AUTOSAR XML (schema 00048)
package /ComponentTypes
  swc implementation AMP_Implementation: behavior=AMP_InternalBehavior
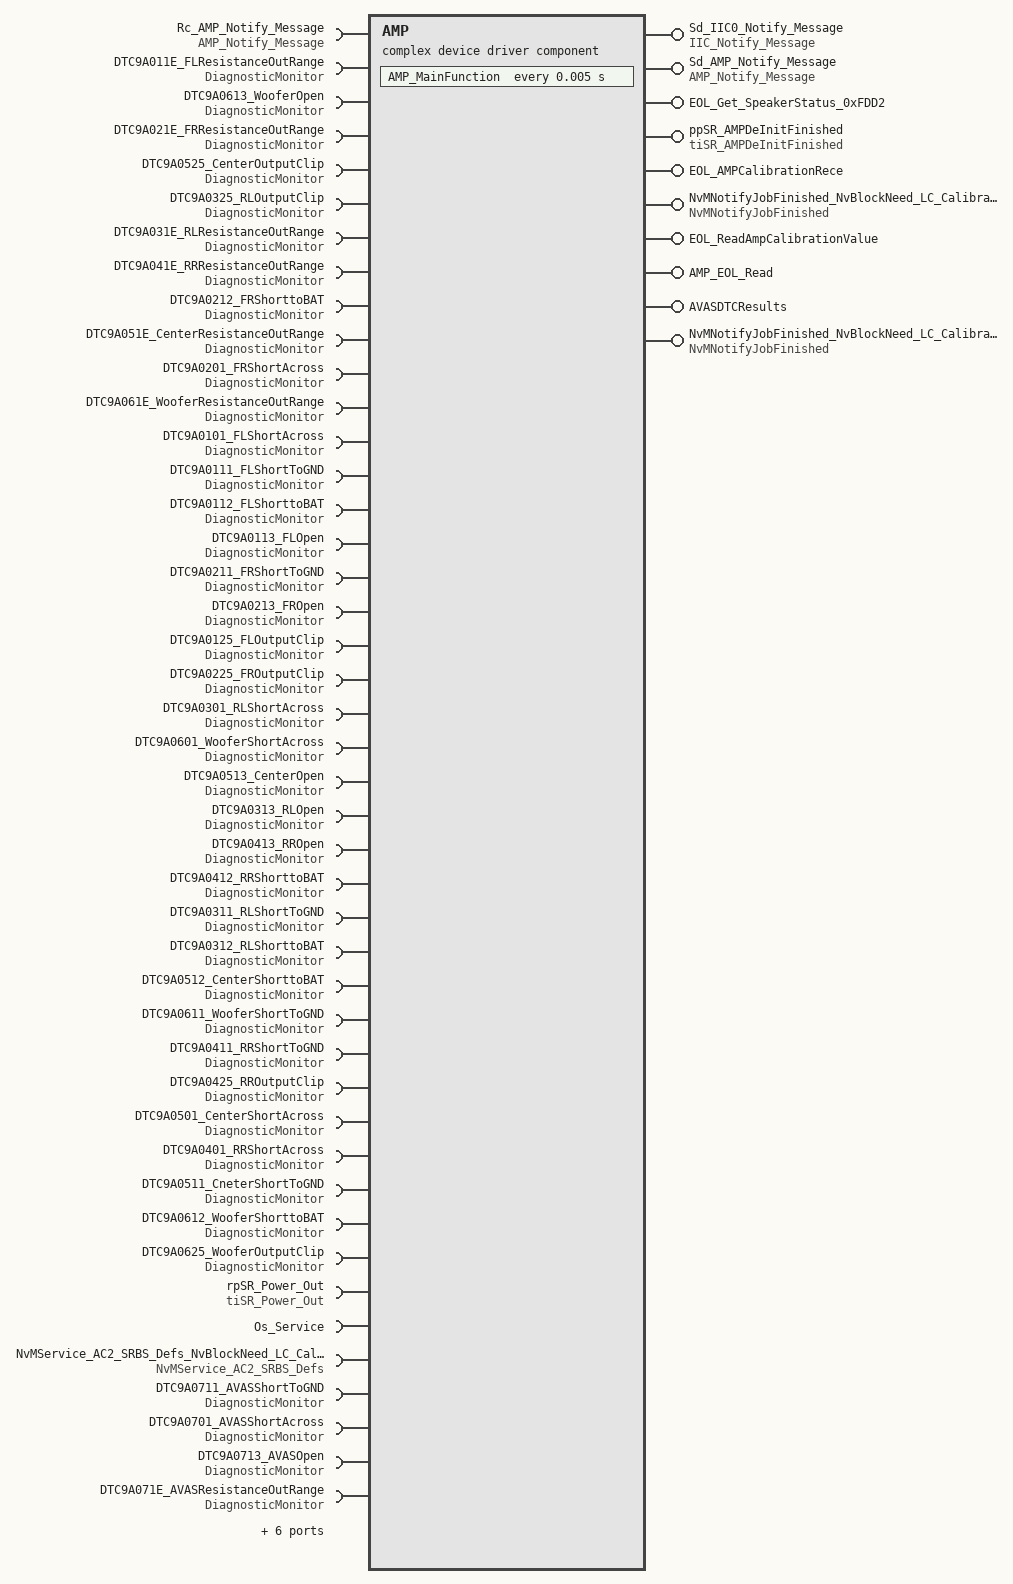
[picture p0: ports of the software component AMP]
  complex device driver sw component type AMP
    provide port Sd_IIC0_Notify_Message: queued-sender-com-spec=Message, provided-interface=IIC_Notify_Message
    provide port Sd_AMP_Notify_Message: nonqueued-sender-com-spec{data-element=Element, init-value=0}, provided-interface=AMP_Notify_Message
    require port Rc_AMP_Notify_Message: nonqueued-receiver-com-spec{data-element=Element, filter=data-filter-type=ALWAYS, init-value=0}, required-interface=AMP_Notify_Message
    provide port EOL_Get_SpeakerStatus_0xFDD2: server-com-spec{operation=EOL_Get_SpeakerStatus_0xFDD2, queue-length=1}, provided-interface=EOL_Get_SpeakerStatus_0xFDD2
    36 x require port, all with required-interface=DiagnosticMonitor:
      DTC9A011E_FLResistanceOutRange
        required-com-specs:
          GetEventExtendedDataRecordEx
          GetEventFreezeFrameDataEx
          GetFaultDetectionCounter
          GetDTCOfEvent
          GetEventTested
          GetEventFailed
          GetEventStatus
          GetEventUdsStatus
          ResetEventDebounceStatus
          ResetEventStatus
          SetEventStatus
      DTC9A0613_WooferOpen
        required-com-specs:
          GetEventExtendedDataRecordEx
          GetEventFreezeFrameDataEx
          GetFaultDetectionCounter
          GetDTCOfEvent
          GetEventTested
          GetEventFailed
          GetEventStatus
          GetEventUdsStatus
          ResetEventDebounceStatus
          ResetEventStatus
          SetEventStatus
      DTC9A021E_FRResistanceOutRange
        required-com-specs:
          GetEventExtendedDataRecordEx
          GetEventFreezeFrameDataEx
          GetFaultDetectionCounter
          GetDTCOfEvent
          GetEventTested
          GetEventFailed
          GetEventStatus
          GetEventUdsStatus
          ResetEventDebounceStatus
          ResetEventStatus
          SetEventStatus
      DTC9A0525_CenterOutputClip
        required-com-specs:
          GetEventExtendedDataRecordEx
          GetEventFreezeFrameDataEx
          GetFaultDetectionCounter
          GetDTCOfEvent
          GetEventTested
          GetEventFailed
          GetEventStatus
          GetEventUdsStatus
          ResetEventDebounceStatus
          ResetEventStatus
          SetEventStatus
      DTC9A0325_RLOutputClip
        required-com-specs:
          GetEventExtendedDataRecordEx
          GetEventFreezeFrameDataEx
          GetFaultDetectionCounter
          GetDTCOfEvent
          GetEventTested
          GetEventFailed
          GetEventStatus
          GetEventUdsStatus
          ResetEventDebounceStatus
          ResetEventStatus
          SetEventStatus
      DTC9A031E_RLResistanceOutRange
        required-com-specs:
          GetEventExtendedDataRecordEx
          GetEventFreezeFrameDataEx
          GetFaultDetectionCounter
          GetDTCOfEvent
          GetEventTested
          GetEventFailed
          GetEventStatus
          GetEventUdsStatus
          ResetEventDebounceStatus
          ResetEventStatus
          SetEventStatus
      DTC9A041E_RRResistanceOutRange
        required-com-specs:
          GetEventExtendedDataRecordEx
          GetEventFreezeFrameDataEx
          GetFaultDetectionCounter
          GetDTCOfEvent
          GetEventTested
          GetEventFailed
          GetEventStatus
          GetEventUdsStatus
          ResetEventDebounceStatus
          ResetEventStatus
          SetEventStatus
      DTC9A0212_FRShorttoBAT
        required-com-specs:
          GetEventExtendedDataRecordEx
          GetEventFreezeFrameDataEx
          GetFaultDetectionCounter
          GetDTCOfEvent
          GetEventTested
          GetEventFailed
          GetEventStatus
          GetEventUdsStatus
          ResetEventDebounceStatus
          ResetEventStatus
          SetEventStatus
      DTC9A051E_CenterResistanceOutRange
        required-com-specs:
          GetEventExtendedDataRecordEx
          GetEventFreezeFrameDataEx
          GetFaultDetectionCounter
          GetDTCOfEvent
          GetEventTested
          GetEventFailed
          GetEventStatus
          GetEventUdsStatus
          ResetEventDebounceStatus
          ResetEventStatus
          SetEventStatus
      DTC9A0201_FRShortAcross
        required-com-specs:
          GetEventExtendedDataRecordEx
          GetEventFreezeFrameDataEx
          GetFaultDetectionCounter
          GetDTCOfEvent
          GetEventTested
          GetEventFailed
          GetEventStatus
          GetEventUdsStatus
          ResetEventDebounceStatus
          ResetEventStatus
          SetEventStatus
      DTC9A061E_WooferResistanceOutRange
        required-com-specs:
          GetEventExtendedDataRecordEx
          GetEventFreezeFrameDataEx
          GetFaultDetectionCounter
          GetDTCOfEvent
          GetEventTested
          GetEventFailed
          GetEventStatus
          GetEventUdsStatus
          ResetEventDebounceStatus
          ResetEventStatus
          SetEventStatus
      DTC9A0101_FLShortAcross
        required-com-specs:
          GetEventExtendedDataRecordEx
          GetEventFreezeFrameDataEx
          GetFaultDetectionCounter
          GetDTCOfEvent
          GetEventTested
          GetEventFailed
          GetEventStatus
          GetEventUdsStatus
          ResetEventDebounceStatus
          ResetEventStatus
          SetEventStatus
      DTC9A0111_FLShortToGND
        required-com-specs:
          GetEventExtendedDataRecordEx
          GetEventFreezeFrameDataEx
          GetFaultDetectionCounter
          GetDTCOfEvent
          GetEventTested
          GetEventFailed
          GetEventStatus
          GetEventUdsStatus
          ResetEventDebounceStatus
          ResetEventStatus
          SetEventStatus
      DTC9A0112_FLShorttoBAT
        required-com-specs:
          GetEventExtendedDataRecordEx
          GetEventFreezeFrameDataEx
          GetFaultDetectionCounter
          GetDTCOfEvent
          GetEventTested
          GetEventFailed
          GetEventStatus
          GetEventUdsStatus
          ResetEventDebounceStatus
          ResetEventStatus
          SetEventStatus
      DTC9A0113_FLOpen
        required-com-specs:
          GetEventExtendedDataRecordEx
          GetEventFreezeFrameDataEx
          GetFaultDetectionCounter
          GetDTCOfEvent
          GetEventTested
          GetEventFailed
          GetEventStatus
          GetEventUdsStatus
          ResetEventDebounceStatus
          ResetEventStatus
          SetEventStatus
      DTC9A0211_FRShortToGND
        required-com-specs:
          GetEventExtendedDataRecordEx
          GetEventFreezeFrameDataEx
          GetFaultDetectionCounter
          GetDTCOfEvent
          GetEventTested
          GetEventFailed
          GetEventStatus
          GetEventUdsStatus
          ResetEventDebounceStatus
          ResetEventStatus
          SetEventStatus
      DTC9A0213_FROpen
        required-com-specs:
          GetEventExtendedDataRecordEx
          GetEventFreezeFrameDataEx
          GetFaultDetectionCounter
          GetDTCOfEvent
          GetEventTested
          GetEventFailed
          GetEventStatus
          GetEventUdsStatus
          ResetEventDebounceStatus
          ResetEventStatus
          SetEventStatus
      DTC9A0125_FLOutputClip
        required-com-specs:
          GetEventExtendedDataRecordEx
          GetEventFreezeFrameDataEx
          GetFaultDetectionCounter
          GetDTCOfEvent
          GetEventTested
          GetEventFailed
          GetEventStatus
          GetEventUdsStatus
          ResetEventDebounceStatus
          ResetEventStatus
          SetEventStatus
      DTC9A0225_FROutputClip
        required-com-specs:
          GetEventExtendedDataRecordEx
          GetEventFreezeFrameDataEx
          GetFaultDetectionCounter
          GetDTCOfEvent
          GetEventTested
          GetEventFailed
          GetEventStatus
          GetEventUdsStatus
          ResetEventDebounceStatus
          ResetEventStatus
          SetEventStatus
      DTC9A0301_RLShortAcross
        required-com-specs:
          GetEventExtendedDataRecordEx
          GetEventFreezeFrameDataEx
          GetFaultDetectionCounter
          GetDTCOfEvent
          GetEventTested
          GetEventFailed
          GetEventStatus
          GetEventUdsStatus
          ResetEventDebounceStatus
          ResetEventStatus
          SetEventStatus
      DTC9A0601_WooferShortAcross
        required-com-specs:
          GetEventExtendedDataRecordEx
          GetEventFreezeFrameDataEx
          GetFaultDetectionCounter
          GetDTCOfEvent
          GetEventTested
          GetEventFailed
          GetEventStatus
          GetEventUdsStatus
          ResetEventDebounceStatus
          ResetEventStatus
          SetEventStatus
      DTC9A0513_CenterOpen
        required-com-specs:
          GetEventExtendedDataRecordEx
          GetEventFreezeFrameDataEx
          GetFaultDetectionCounter
          GetDTCOfEvent
          GetEventTested
          GetEventFailed
          GetEventStatus
          GetEventUdsStatus
          ResetEventDebounceStatus
          ResetEventStatus
          SetEventStatus
      DTC9A0313_RLOpen
        required-com-specs:
          GetEventExtendedDataRecordEx
          GetEventFreezeFrameDataEx
          GetFaultDetectionCounter
          GetDTCOfEvent
          GetEventTested
          GetEventFailed
          GetEventStatus
          GetEventUdsStatus
          ResetEventDebounceStatus
          ResetEventStatus
          SetEventStatus
      DTC9A0413_RROpen
        required-com-specs:
          GetEventExtendedDataRecordEx
          GetEventFreezeFrameDataEx
          GetFaultDetectionCounter
          GetDTCOfEvent
          GetEventTested
          GetEventFailed
          GetEventStatus
          GetEventUdsStatus
          ResetEventDebounceStatus
          ResetEventStatus
          SetEventStatus
      DTC9A0412_RRShorttoBAT
        required-com-specs:
          GetEventExtendedDataRecordEx
          GetEventFreezeFrameDataEx
          GetFaultDetectionCounter
          GetDTCOfEvent
          GetEventTested
          GetEventFailed
          GetEventStatus
          GetEventUdsStatus
          ResetEventDebounceStatus
          ResetEventStatus
          SetEventStatus
      DTC9A0311_RLShortToGND
        required-com-specs:
          GetEventExtendedDataRecordEx
          GetEventFreezeFrameDataEx
          GetFaultDetectionCounter
          GetDTCOfEvent
          GetEventTested
          GetEventFailed
          GetEventStatus
          GetEventUdsStatus
          ResetEventDebounceStatus
          ResetEventStatus
          SetEventStatus
      DTC9A0312_RLShorttoBAT
        required-com-specs:
          GetEventExtendedDataRecordEx
          GetEventFreezeFrameDataEx
          GetFaultDetectionCounter
          GetDTCOfEvent
          GetEventTested
          GetEventFailed
          GetEventStatus
          GetEventUdsStatus
          ResetEventDebounceStatus
          ResetEventStatus
          SetEventStatus
      DTC9A0512_CenterShorttoBAT
        required-com-specs:
          GetEventExtendedDataRecordEx
          GetEventFreezeFrameDataEx
          GetFaultDetectionCounter
          GetDTCOfEvent
          GetEventTested
          GetEventFailed
          GetEventStatus
          GetEventUdsStatus
          ResetEventDebounceStatus
          ResetEventStatus
          SetEventStatus
      DTC9A0611_WooferShortToGND
        required-com-specs:
          GetEventExtendedDataRecordEx
          GetEventFreezeFrameDataEx
          GetFaultDetectionCounter
          GetDTCOfEvent
          GetEventTested
          GetEventFailed
          GetEventStatus
          GetEventUdsStatus
          ResetEventDebounceStatus
          ResetEventStatus
          SetEventStatus
      DTC9A0411_RRShortToGND
        required-com-specs:
          GetEventExtendedDataRecordEx
          GetEventFreezeFrameDataEx
          GetFaultDetectionCounter
          GetDTCOfEvent
          GetEventTested
          GetEventFailed
          GetEventStatus
          GetEventUdsStatus
          ResetEventDebounceStatus
          ResetEventStatus
          SetEventStatus
      DTC9A0425_RROutputClip
        required-com-specs:
          GetEventExtendedDataRecordEx
          GetEventFreezeFrameDataEx
          GetFaultDetectionCounter
          GetDTCOfEvent
          GetEventTested
          GetEventFailed
          GetEventStatus
          GetEventUdsStatus
          ResetEventDebounceStatus
          ResetEventStatus
          SetEventStatus
      DTC9A0501_CenterShortAcross
        required-com-specs:
          GetEventExtendedDataRecordEx
          GetEventFreezeFrameDataEx
          GetFaultDetectionCounter
          GetDTCOfEvent
          GetEventTested
          GetEventFailed
          GetEventStatus
          GetEventUdsStatus
          ResetEventDebounceStatus
          ResetEventStatus
          SetEventStatus
      DTC9A0401_RRShortAcross
        required-com-specs:
          GetEventExtendedDataRecordEx
          GetEventFreezeFrameDataEx
          GetFaultDetectionCounter
          GetDTCOfEvent
          GetEventTested
          GetEventFailed
          GetEventStatus
          GetEventUdsStatus
          ResetEventDebounceStatus
          ResetEventStatus
          SetEventStatus
      DTC9A0511_CneterShortToGND
        required-com-specs:
          GetEventExtendedDataRecordEx
          GetEventFreezeFrameDataEx
          GetFaultDetectionCounter
          GetDTCOfEvent
          GetEventTested
          GetEventFailed
          GetEventStatus
          GetEventUdsStatus
          ResetEventDebounceStatus
          ResetEventStatus
          SetEventStatus
      DTC9A0612_WooferShorttoBAT
        required-com-specs:
          GetEventExtendedDataRecordEx
          GetEventFreezeFrameDataEx
          GetFaultDetectionCounter
          GetDTCOfEvent
          GetEventTested
          GetEventFailed
          GetEventStatus
          GetEventUdsStatus
          ResetEventDebounceStatus
          ResetEventStatus
          SetEventStatus
      DTC9A0625_WooferOutputClip
        required-com-specs:
          GetEventExtendedDataRecordEx
          GetEventFreezeFrameDataEx
          GetFaultDetectionCounter
          GetDTCOfEvent
          GetEventTested
          GetEventFailed
          GetEventStatus
          GetEventUdsStatus
          ResetEventDebounceStatus
          ResetEventStatus
          SetEventStatus
    provide port ppSR_AMPDeInitFinished: nonqueued-sender-com-spec{data-element=State, init-value=0}, provided-interface=tiSR_AMPDeInitFinished
    require port rpSR_Power_Out: nonqueued-receiver-com-spec{data-element=SystemStateOut, filter=data-filter-type=ALWAYS, init-value=constant-reference=PowerOutInit}, required-interface=tiSR_Power_Out
    require port Os_Service: required-com-specs=[GetElapsedValue, GetCounterValue], required-interface=Os_Service
    provide port EOL_AMPCalibrationRece: nonqueued-sender-com-spec{data-element=EOLReceive, init-value=10 x 0}, provided-interface=EOL_AMPCalibrationRece
    require port NvMService_AC2_SRBS_Defs_NvBlockNeed_LC_Calibration: required-com-specs=[WriteBlock, SetRamBlockStatus, RestoreBlockDefaults, ReadBlock, GetErrorStatus], required-interface=NvMService_AC2_SRBS_Defs
    provide port NvMNotifyJobFinished_NvBlockNeed_LC_Calibration: server-com-spec{operation=JobFinished, queue-length=1}, provided-interface=NvMNotifyJobFinished
    6 x require port, all with required-interface=DiagnosticMonitor:
      DTC9A0711_AVASShortToGND
        required-com-specs:
          GetEventExtendedDataRecordEx
          GetEventFreezeFrameDataEx
          GetFaultDetectionCounter
          GetDTCOfEvent
          GetEventTested
          GetEventFailed
          GetEventStatus
          GetEventUdsStatus
          ResetEventDebounceStatus
          ResetEventStatus
          SetEventStatus
      DTC9A0701_AVASShortAcross
        required-com-specs:
          GetEventExtendedDataRecordEx
          GetEventFreezeFrameDataEx
          GetFaultDetectionCounter
          GetDTCOfEvent
          GetEventTested
          GetEventFailed
          GetEventStatus
          GetEventUdsStatus
          ResetEventDebounceStatus
          ResetEventStatus
          SetEventStatus
      DTC9A0713_AVASOpen
        required-com-specs:
          GetEventExtendedDataRecordEx
          GetEventFreezeFrameDataEx
          GetFaultDetectionCounter
          GetDTCOfEvent
          GetEventTested
          GetEventFailed
          GetEventStatus
          GetEventUdsStatus
          ResetEventDebounceStatus
          ResetEventStatus
          SetEventStatus
      DTC9A071E_AVASResistanceOutRange
        required-com-specs:
          GetEventExtendedDataRecordEx
          GetEventFreezeFrameDataEx
          GetFaultDetectionCounter
          GetDTCOfEvent
          GetEventTested
          GetEventFailed
          GetEventStatus
          GetEventUdsStatus
          ResetEventDebounceStatus
          ResetEventStatus
          SetEventStatus
      DTC9A0712_AVASShorttoBAT
        required-com-specs:
          GetEventExtendedDataRecordEx
          GetEventFreezeFrameDataEx
          GetFaultDetectionCounter
          GetDTCOfEvent
          GetEventTested
          GetEventFailed
          GetEventStatus
          GetEventUdsStatus
          ResetEventDebounceStatus
          ResetEventStatus
          SetEventStatus
      DTC9A0725_AVASOutputClip
        required-com-specs:
          GetEventExtendedDataRecordEx
          GetEventFreezeFrameDataEx
          GetFaultDetectionCounter
          GetDTCOfEvent
          GetEventTested
          GetEventFailed
          GetEventStatus
          GetEventUdsStatus
          ResetEventDebounceStatus
          ResetEventStatus
          SetEventStatus
    provide port EOL_ReadAmpCalibrationValue: nonqueued-sender-com-spec{data-element=AmpCalibrationValue, init-value=[17, 0, 0, 0, 0, 0, 0, 0, 0]}, provided-interface=EOL_ReadAmpCalibrationValue
    require port EOL_AMPCalibration: nonqueued-receiver-com-spec{data-element=AMPCalibration, filter=data-filter-type=ALWAYS, init-value=0}, required-interface=EOL_AMPCalibration
    provide port AMP_EOL_Read: server-com-spec{operation=Operation, queue-length=1}, provided-interface=AMP_EOL_Read
    provide port AVASDTCResults: nonqueued-sender-com-spec{data-element=AVASDTC, init-value=fields=[ElementConstant:2, ElementConstant_1:2, ElementConstant_2:2, ElementConstant_3:2, ElementConstant_4:2, ElementConstant_5:2]}, provided-interface=AVASDTCResults
    provide port NvMNotifyJobFinished_NvBlockNeed_LC_Calibration2: server-com-spec{operation=JobFinished, queue-length=1}, provided-interface=NvMNotifyJobFinished
    require port NvMService_AC2_SRBS_Defs_NvBlockNeed_LC_Calibration2: required-com-specs=[WriteBlock, SetRamBlockStatus, RestoreBlockDefaults, ReadBlock, GetErrorStatus], required-interface=NvMService_AC2_SRBS_Defs
    require port rpSR_piDiagMonitorReInitFlag: nonqueued-receiver-com-spec{data-element=ChangeCounter, filter=data-filter-type=ALWAYS, init-value=0}, required-interface=piDiagMonitorReInitFlag
    require port VConfig_GetKindConfig: client-com-spec=Operation_VConfig_GetKindConfig, required-interface=VConfig_GetKindConfig
    behavior AMP_InternalBehavior
      ar-typed-per-instance-memorys:
        data NvBlockNeed_LC_Calibration_MirrorBlock: sw-calibration-access=READ-ONLY, type=A_u8_20
        data NvBlockNeed_LC_Calibration2_MirrorBlock: sw-calibration-access=READ-ONLY, type=A_u8_20
      timing event TMT_AMP_MainFunction: start-on-event=AMP_MainFunction, period=0.005
      data received event DRT_AMP_Event_MainFunction_Rc_AMP_Notify_Message_Element: start-on-event=AMP_Event_MainFunction, data=Rc_AMP_Notify_Message.Element
      4 x operation invoked event:
        OIT_EOL_Get_SpeakerStatus_0xFDD2_EOL_Get_SpeakerStatus_0xFDD2_EOL_Get_SpeakerStatus_0xFDD2_EOL_Get_SpeakerStatus_0xFDD2: start-on-event=EOL_Get_SpeakerStatus_0xFDD2_EOL_Get_SpeakerStatus_0xFDD2, operation=EOL_Get_SpeakerStatus_0xFDD2.EOL_Get_SpeakerStatus_0xFDD2
        OIT_NvMNotifyJobFinished_NvBlockNeed_LC_Calibration_JobFinished_NvMNotifyJobFinished_NvBlockNeed_LC_Calibration_JobFinished: start-on-event=NvBlockNeed_LC_Calibration_JobFinished, operation=NvMNotifyJobFinished_NvBlockNeed_LC_Calibration.JobFinished
        OIT_AMP_EOL_Read_Operation_AMP_EOL_Read_Operation: start-on-event=AMP_EOL_Read_Operation, operation=AMP_EOL_Read.Operation
        OIT_NvMNotifyJobFinished_NvBlockNeed_LC_Calibration2_JobFinished_NvMNotifyJobFinished_NvBlockNeed_LC_Calibration2_JobFinished: start-on-event=NvBlockNeed_LC_Calibration2_JobFinished, operation=NvMNotifyJobFinished_NvBlockNeed_LC_Calibration2.JobFinished
      6 x runnable:
        AMP_MainFunction
          data-receive-point-by-arguments:
            access REC_rpSR_Power_Out_SystemStateOut: accessed-variable=rpSR_Power_Out.SystemStateOut
            access REC_EOL_AMPCalibration_AMPCalibration: accessed-variable=EOL_AMPCalibration.AMPCalibration
            access REC_rpSR_piDiagMonitorReInitFlag_ChangeCounter: accessed-variable=rpSR_piDiagMonitorReInitFlag.ChangeCounter
          data-send-points:
            6 x access:
              SEND_Sd_IIC0_Notify_Message_Message: accessed-variable=Sd_IIC0_Notify_Message.Message
              SEND_Sd_AMP_Notify_Message_Element: accessed-variable=Sd_AMP_Notify_Message.Element
              SEND_ppSR_AMPDeInitFinished_State: accessed-variable=ppSR_AMPDeInitFinished.State
              SEND_EOL_AMPCalibrationRece_EOLReceive: accessed-variable=EOL_AMPCalibrationRece.EOLReceive
              SEND_EOL_ReadAmpCalibrationValue_AmpCalibrationValue: accessed-variable=EOL_ReadAmpCalibrationValue.AmpCalibrationValue
              SEND_AVASDTCResults_AVASDTC: accessed-variable=AVASDTCResults.AVASDTC
          sync call SC_VConfig_GetKindConfig_Operation_VConfig_GetKindConfig: operation=VConfig_GetKindConfig.Operation_VConfig_GetKindConfig
        AMP_Event_MainFunction
          data-receive-point-by-arguments:
            access REC_Rc_AMP_Notify_Message_Element: accessed-variable=Rc_AMP_Notify_Message.Element
          150 x sync call:
            SC_DTC9A011E_FLResistanceOutRange_SetEventStatus: operation=DTC9A011E_FLResistanceOutRange.SetEventStatus
            SC_DTC9A021E_FRResistanceOutRange_SetEventStatus: operation=DTC9A021E_FRResistanceOutRange.SetEventStatus
            SC_DTC9A031E_RLResistanceOutRange_SetEventStatus: operation=DTC9A031E_RLResistanceOutRange.SetEventStatus
            SC_DTC9A041E_RRResistanceOutRange_SetEventStatus: operation=DTC9A041E_RRResistanceOutRange.SetEventStatus
            SC_DTC9A051E_CenterResistanceOutRange_SetEventStatus: operation=DTC9A051E_CenterResistanceOutRange.SetEventStatus
            SC_DTC9A061E_WooferResistanceOutRange_SetEventStatus: operation=DTC9A061E_WooferResistanceOutRange.SetEventStatus
            SC_DTC9A0101_FLShortAcross_SetEventStatus: operation=DTC9A0101_FLShortAcross.SetEventStatus
            SC_DTC9A0111_FLShortToGND_SetEventStatus: operation=DTC9A0111_FLShortToGND.SetEventStatus
            SC_DTC9A0112_FLShorttoBAT_SetEventStatus: operation=DTC9A0112_FLShorttoBAT.SetEventStatus
            SC_DTC9A0113_FLOpen_SetEventStatus: operation=DTC9A0113_FLOpen.SetEventStatus
            SC_DTC9A0125_FLOutputClip_SetEventStatus: operation=DTC9A0125_FLOutputClip.SetEventStatus
            SC_DTC9A0201_FRShortAcross_SetEventStatus: operation=DTC9A0201_FRShortAcross.SetEventStatus
            SC_DTC9A0211_FRShortToGND_SetEventStatus: operation=DTC9A0211_FRShortToGND.SetEventStatus
            SC_DTC9A0212_FRShorttoBAT_SetEventStatus: operation=DTC9A0212_FRShorttoBAT.SetEventStatus
            SC_DTC9A0213_FROpen_SetEventStatus: operation=DTC9A0213_FROpen.SetEventStatus
            SC_DTC9A0225_FROutputClip_SetEventStatus: operation=DTC9A0225_FROutputClip.SetEventStatus
            SC_DTC9A0301_RLShortAcross_SetEventStatus: operation=DTC9A0301_RLShortAcross.SetEventStatus
            SC_DTC9A0311_RLShortToGND_SetEventStatus: operation=DTC9A0311_RLShortToGND.SetEventStatus
            SC_DTC9A0312_RLShorttoBAT_SetEventStatus: operation=DTC9A0312_RLShorttoBAT.SetEventStatus
            SC_DTC9A0313_RLOpen_SetEventStatus: operation=DTC9A0313_RLOpen.SetEventStatus
            SC_DTC9A0325_RLOutputClip_SetEventStatus: operation=DTC9A0325_RLOutputClip.SetEventStatus
            SC_DTC9A0401_RRShortAcross_SetEventStatus: operation=DTC9A0401_RRShortAcross.SetEventStatus
            SC_DTC9A0411_RRShortToGND_SetEventStatus: operation=DTC9A0411_RRShortToGND.SetEventStatus
            SC_DTC9A0412_RRShorttoBAT_SetEventStatus: operation=DTC9A0412_RRShorttoBAT.SetEventStatus
            SC_DTC9A0413_RROpen_SetEventStatus: operation=DTC9A0413_RROpen.SetEventStatus
            SC_DTC9A0425_RROutputClip_SetEventStatus: operation=DTC9A0425_RROutputClip.SetEventStatus
            SC_DTC9A0501_CenterShortAcross_SetEventStatus: operation=DTC9A0501_CenterShortAcross.SetEventStatus
            SC_DTC9A0511_CneterShortToGND_SetEventStatus: operation=DTC9A0511_CneterShortToGND.SetEventStatus
            SC_DTC9A0512_CenterShorttoBAT_SetEventStatus: operation=DTC9A0512_CenterShorttoBAT.SetEventStatus
            SC_DTC9A0513_CenterOpen_SetEventStatus: operation=DTC9A0513_CenterOpen.SetEventStatus
            SC_DTC9A0525_CenterOutputClip_SetEventStatus: operation=DTC9A0525_CenterOutputClip.SetEventStatus
            SC_DTC9A0601_WooferShortAcross_SetEventStatus: operation=DTC9A0601_WooferShortAcross.SetEventStatus
            SC_DTC9A0611_WooferShortToGND_SetEventStatus: operation=DTC9A0611_WooferShortToGND.SetEventStatus
            SC_DTC9A0612_WooferShorttoBAT_SetEventStatus: operation=DTC9A0612_WooferShorttoBAT.SetEventStatus
            SC_DTC9A0613_WooferOpen_SetEventStatus: operation=DTC9A0613_WooferOpen.SetEventStatus
            SC_DTC9A0625_WooferOutputClip_SetEventStatus: operation=DTC9A0625_WooferOutputClip.SetEventStatus
            SC_DTC9A0625_WooferOutputClip_ResetEventStatus: operation=DTC9A0625_WooferOutputClip.ResetEventStatus
            SC_DTC9A0613_WooferOpen_ResetEventStatus: operation=DTC9A0613_WooferOpen.ResetEventStatus
            SC_DTC9A0612_WooferShorttoBAT_ResetEventStatus: operation=DTC9A0612_WooferShorttoBAT.ResetEventStatus
            SC_DTC9A0611_WooferShortToGND_ResetEventStatus: operation=DTC9A0611_WooferShortToGND.ResetEventStatus
            SC_DTC9A0601_WooferShortAcross_ResetEventStatus: operation=DTC9A0601_WooferShortAcross.ResetEventStatus
            SC_DTC9A0525_CenterOutputClip_ResetEventStatus: operation=DTC9A0525_CenterOutputClip.ResetEventStatus
            SC_DTC9A0513_CenterOpen_ResetEventStatus: operation=DTC9A0513_CenterOpen.ResetEventStatus
            SC_DTC9A0512_CenterShorttoBAT_ResetEventStatus: operation=DTC9A0512_CenterShorttoBAT.ResetEventStatus
            SC_DTC9A0511_CneterShortToGND_ResetEventStatus: operation=DTC9A0511_CneterShortToGND.ResetEventStatus
            SC_DTC9A0501_CenterShortAcross_ResetEventStatus: operation=DTC9A0501_CenterShortAcross.ResetEventStatus
            SC_DTC9A0425_RROutputClip_ResetEventStatus: operation=DTC9A0425_RROutputClip.ResetEventStatus
            SC_DTC9A0413_RROpen_ResetEventStatus: operation=DTC9A0413_RROpen.ResetEventStatus
            SC_DTC9A0412_RRShorttoBAT_ResetEventStatus: operation=DTC9A0412_RRShorttoBAT.ResetEventStatus
            SC_DTC9A0411_RRShortToGND_ResetEventStatus: operation=DTC9A0411_RRShortToGND.ResetEventStatus
            SC_DTC9A0401_RRShortAcross_ResetEventStatus: operation=DTC9A0401_RRShortAcross.ResetEventStatus
            SC_DTC9A0325_RLOutputClip_ResetEventStatus: operation=DTC9A0325_RLOutputClip.ResetEventStatus
            SC_DTC9A0313_RLOpen_ResetEventStatus: operation=DTC9A0313_RLOpen.ResetEventStatus
            SC_DTC9A0312_RLShorttoBAT_ResetEventStatus: operation=DTC9A0312_RLShorttoBAT.ResetEventStatus
            SC_DTC9A0311_RLShortToGND_ResetEventStatus: operation=DTC9A0311_RLShortToGND.ResetEventStatus
            SC_DTC9A0301_RLShortAcross_ResetEventStatus: operation=DTC9A0301_RLShortAcross.ResetEventStatus
            SC_DTC9A0225_FROutputClip_ResetEventStatus: operation=DTC9A0225_FROutputClip.ResetEventStatus
            SC_DTC9A0213_FROpen_ResetEventStatus: operation=DTC9A0213_FROpen.ResetEventStatus
            SC_DTC9A0212_FRShorttoBAT_ResetEventStatus: operation=DTC9A0212_FRShorttoBAT.ResetEventStatus
            SC_DTC9A0211_FRShortToGND_ResetEventStatus: operation=DTC9A0211_FRShortToGND.ResetEventStatus
            SC_DTC9A0201_FRShortAcross_ResetEventStatus: operation=DTC9A0201_FRShortAcross.ResetEventStatus
            SC_DTC9A0125_FLOutputClip_ResetEventStatus: operation=DTC9A0125_FLOutputClip.ResetEventStatus
            SC_DTC9A0113_FLOpen_ResetEventStatus: operation=DTC9A0113_FLOpen.ResetEventStatus
            SC_DTC9A0112_FLShorttoBAT_ResetEventStatus: operation=DTC9A0112_FLShorttoBAT.ResetEventStatus
            SC_DTC9A0111_FLShortToGND_ResetEventStatus: operation=DTC9A0111_FLShortToGND.ResetEventStatus
            SC_DTC9A0101_FLShortAcross_ResetEventStatus: operation=DTC9A0101_FLShortAcross.ResetEventStatus
            SC_DTC9A061E_WooferResistanceOutRange_ResetEventStatus: operation=DTC9A061E_WooferResistanceOutRange.ResetEventStatus
            SC_DTC9A051E_CenterResistanceOutRange_ResetEventStatus: operation=DTC9A051E_CenterResistanceOutRange.ResetEventStatus
            SC_DTC9A041E_RRResistanceOutRange_ResetEventStatus: operation=DTC9A041E_RRResistanceOutRange.ResetEventStatus
            SC_DTC9A031E_RLResistanceOutRange_ResetEventStatus: operation=DTC9A031E_RLResistanceOutRange.ResetEventStatus
            SC_DTC9A021E_FRResistanceOutRange_ResetEventStatus: operation=DTC9A021E_FRResistanceOutRange.ResetEventStatus
            SC_DTC9A011E_FLResistanceOutRange_ResetEventStatus: operation=DTC9A011E_FLResistanceOutRange.ResetEventStatus
            SC_Os_Service_GetCounterValue: operation=Os_Service.GetCounterValue
            SC_Os_Service_GetElapsedValue: operation=Os_Service.GetElapsedValue
            SC_NvMService_AC2_SRBS_Defs_NvBlockNeed_LC_Calibration_GetErrorStatus: operation=NvMService_AC2_SRBS_Defs_NvBlockNeed_LC_Calibration.GetErrorStatus
            SC_NvMService_AC2_SRBS_Defs_NvBlockNeed_LC_Calibration_ReadBlock: operation=NvMService_AC2_SRBS_Defs_NvBlockNeed_LC_Calibration.ReadBlock
            SC_NvMService_AC2_SRBS_Defs_NvBlockNeed_LC_Calibration_RestoreBlockDefaults: operation=NvMService_AC2_SRBS_Defs_NvBlockNeed_LC_Calibration.RestoreBlockDefaults
            SC_NvMService_AC2_SRBS_Defs_NvBlockNeed_LC_Calibration_SetRamBlockStatus: operation=NvMService_AC2_SRBS_Defs_NvBlockNeed_LC_Calibration.SetRamBlockStatus
            SC_NvMService_AC2_SRBS_Defs_NvBlockNeed_LC_Calibration_WriteBlock: operation=NvMService_AC2_SRBS_Defs_NvBlockNeed_LC_Calibration.WriteBlock
            SC_DTC9A071E_AVASResistanceOutRange_ResetEventDebounceStatus: operation=DTC9A071E_AVASResistanceOutRange.ResetEventDebounceStatus
            SC_DTC9A0701_AVASShortAcross_GetDTCOfEvent: operation=DTC9A0701_AVASShortAcross.GetDTCOfEvent
            SC_DTC9A0701_AVASShortAcross_GetEventExtendedDataRecordEx: operation=DTC9A0701_AVASShortAcross.GetEventExtendedDataRecordEx
            SC_DTC9A0701_AVASShortAcross_GetEventFailed: operation=DTC9A0701_AVASShortAcross.GetEventFailed
            SC_DTC9A0701_AVASShortAcross_GetEventFreezeFrameDataEx: operation=DTC9A0701_AVASShortAcross.GetEventFreezeFrameDataEx
            SC_DTC9A0701_AVASShortAcross_GetEventStatus: operation=DTC9A0701_AVASShortAcross.GetEventStatus
            SC_DTC9A0701_AVASShortAcross_GetEventTested: operation=DTC9A0701_AVASShortAcross.GetEventTested
            SC_DTC9A0701_AVASShortAcross_GetEventUdsStatus: operation=DTC9A0701_AVASShortAcross.GetEventUdsStatus
            SC_DTC9A0701_AVASShortAcross_GetFaultDetectionCounter: operation=DTC9A0701_AVASShortAcross.GetFaultDetectionCounter
            SC_DTC9A0701_AVASShortAcross_ResetEventDebounceStatus: operation=DTC9A0701_AVASShortAcross.ResetEventDebounceStatus
            SC_DTC9A0701_AVASShortAcross_ResetEventStatus: operation=DTC9A0701_AVASShortAcross.ResetEventStatus
            SC_DTC9A0701_AVASShortAcross_SetEventStatus: operation=DTC9A0701_AVASShortAcross.SetEventStatus
            SC_DTC9A0711_WooferShortToGND_GetDTCOfEvent: operation=DTC9A0711_AVASShortToGND.GetDTCOfEvent
            SC_DTC9A0711_WooferShortToGND_GetEventExtendedDataRecordEx: operation=DTC9A0711_AVASShortToGND.GetEventExtendedDataRecordEx
            SC_DTC9A0711_WooferShortToGND_GetEventFailed: operation=DTC9A0711_AVASShortToGND.GetEventFailed
            SC_DTC9A0711_WooferShortToGND_GetEventFreezeFrameDataEx: operation=DTC9A0711_AVASShortToGND.GetEventFreezeFrameDataEx
            SC_DTC9A0711_WooferShortToGND_GetEventStatus: operation=DTC9A0711_AVASShortToGND.GetEventStatus
            SC_DTC9A0711_WooferShortToGND_GetEventTested: operation=DTC9A0711_AVASShortToGND.GetEventTested
            SC_DTC9A0711_WooferShortToGND_GetEventUdsStatus: operation=DTC9A0711_AVASShortToGND.GetEventUdsStatus
            SC_DTC9A0711_WooferShortToGND_GetFaultDetectionCounter: operation=DTC9A0711_AVASShortToGND.GetFaultDetectionCounter
            SC_DTC9A0711_WooferShortToGND_ResetEventDebounceStatus: operation=DTC9A0711_AVASShortToGND.ResetEventDebounceStatus
            SC_DTC9A0711_WooferShortToGND_ResetEventStatus: operation=DTC9A0711_AVASShortToGND.ResetEventStatus
            SC_DTC9A0711_WooferShortToGND_SetEventStatus: operation=DTC9A0711_AVASShortToGND.SetEventStatus
            SC_DTC9A0712_AVASShorttoBAT_GetDTCOfEvent: operation=DTC9A0712_AVASShorttoBAT.GetDTCOfEvent
            SC_DTC9A0712_AVASShorttoBAT_GetEventExtendedDataRecordEx: operation=DTC9A0712_AVASShorttoBAT.GetEventExtendedDataRecordEx
            SC_DTC9A0712_AVASShorttoBAT_GetEventFailed: operation=DTC9A0712_AVASShorttoBAT.GetEventFailed
            SC_DTC9A0712_AVASShorttoBAT_GetEventFreezeFrameDataEx: operation=DTC9A0712_AVASShorttoBAT.GetEventFreezeFrameDataEx
            SC_DTC9A0712_AVASShorttoBAT_GetEventStatus: operation=DTC9A0712_AVASShorttoBAT.GetEventStatus
            SC_DTC9A0712_AVASShorttoBAT_GetEventTested: operation=DTC9A0712_AVASShorttoBAT.GetEventTested
            SC_DTC9A0712_AVASShorttoBAT_GetEventUdsStatus: operation=DTC9A0712_AVASShorttoBAT.GetEventUdsStatus
            SC_DTC9A0712_AVASShorttoBAT_GetFaultDetectionCounter: operation=DTC9A0712_AVASShorttoBAT.GetFaultDetectionCounter
            SC_DTC9A0712_AVASShorttoBAT_ResetEventDebounceStatus: operation=DTC9A0712_AVASShorttoBAT.ResetEventDebounceStatus
            SC_DTC9A0712_AVASShorttoBAT_ResetEventStatus: operation=DTC9A0712_AVASShorttoBAT.ResetEventStatus
            SC_DTC9A0712_AVASShorttoBAT_SetEventStatus: operation=DTC9A0712_AVASShorttoBAT.SetEventStatus
            SC_DTC9A0713_AVASOpen_GetDTCOfEvent: operation=DTC9A0713_AVASOpen.GetDTCOfEvent
            SC_DTC9A0713_AVASOpen_GetEventExtendedDataRecordEx: operation=DTC9A0713_AVASOpen.GetEventExtendedDataRecordEx
            SC_DTC9A0713_AVASOpen_GetEventFailed: operation=DTC9A0713_AVASOpen.GetEventFailed
            SC_DTC9A0713_AVASOpen_GetEventFreezeFrameDataEx: operation=DTC9A0713_AVASOpen.GetEventFreezeFrameDataEx
            SC_DTC9A0713_AVASOpen_GetEventStatus: operation=DTC9A0713_AVASOpen.GetEventStatus
            SC_DTC9A0713_AVASOpen_GetEventTested: operation=DTC9A0713_AVASOpen.GetEventTested
            SC_DTC9A0713_AVASOpen_GetEventUdsStatus: operation=DTC9A0713_AVASOpen.GetEventUdsStatus
            SC_DTC9A0713_AVASOpen_GetFaultDetectionCounter: operation=DTC9A0713_AVASOpen.GetFaultDetectionCounter
            SC_DTC9A0713_AVASOpen_ResetEventDebounceStatus: operation=DTC9A0713_AVASOpen.ResetEventDebounceStatus
            SC_DTC9A0713_AVASOpen_ResetEventStatus: operation=DTC9A0713_AVASOpen.ResetEventStatus
            SC_DTC9A0713_AVASOpen_SetEventStatus: operation=DTC9A0713_AVASOpen.SetEventStatus
            SC_DTC9A071E_AVASResistanceOutRange_GetDTCOfEvent: operation=DTC9A071E_AVASResistanceOutRange.GetDTCOfEvent
            SC_DTC9A071E_AVASResistanceOutRange_GetEventExtendedDataRecordEx: operation=DTC9A071E_AVASResistanceOutRange.GetEventExtendedDataRecordEx
            SC_DTC9A071E_AVASResistanceOutRange_GetEventFailed: operation=DTC9A071E_AVASResistanceOutRange.GetEventFailed
            SC_DTC9A071E_AVASResistanceOutRange_GetEventFreezeFrameDataEx: operation=DTC9A071E_AVASResistanceOutRange.GetEventFreezeFrameDataEx
            SC_DTC9A071E_AVASResistanceOutRange_GetEventStatus: operation=DTC9A071E_AVASResistanceOutRange.GetEventStatus
            SC_DTC9A071E_AVASResistanceOutRange_GetEventTested: operation=DTC9A071E_AVASResistanceOutRange.GetEventTested
            SC_DTC9A071E_AVASResistanceOutRange_GetEventUdsStatus: operation=DTC9A071E_AVASResistanceOutRange.GetEventUdsStatus
            SC_DTC9A071E_AVASResistanceOutRange_GetFaultDetectionCounter: operation=DTC9A071E_AVASResistanceOutRange.GetFaultDetectionCounter
            SC_DTC9A071E_AVASResistanceOutRange_ResetEventStatus: operation=DTC9A071E_AVASResistanceOutRange.ResetEventStatus
            SC_DTC9A071E_AVASResistanceOutRange_SetEventStatus: operation=DTC9A071E_AVASResistanceOutRange.SetEventStatus
            SC_DTC9A0725_AVASOutputClip_GetDTCOfEvent: operation=DTC9A0725_AVASOutputClip.GetDTCOfEvent
            SC_DTC9A0725_AVASOutputClip_GetEventExtendedDataRecordEx: operation=DTC9A0725_AVASOutputClip.GetEventExtendedDataRecordEx
            SC_DTC9A0725_AVASOutputClip_GetEventFailed: operation=DTC9A0725_AVASOutputClip.GetEventFailed
            SC_DTC9A0725_AVASOutputClip_GetEventFreezeFrameDataEx: operation=DTC9A0725_AVASOutputClip.GetEventFreezeFrameDataEx
            SC_DTC9A0725_AVASOutputClip_GetEventStatus: operation=DTC9A0725_AVASOutputClip.GetEventStatus
            SC_DTC9A0725_AVASOutputClip_GetEventTested: operation=DTC9A0725_AVASOutputClip.GetEventTested
            SC_DTC9A0725_AVASOutputClip_GetEventUdsStatus: operation=DTC9A0725_AVASOutputClip.GetEventUdsStatus
            SC_DTC9A0725_AVASOutputClip_GetFaultDetectionCounter: operation=DTC9A0725_AVASOutputClip.GetFaultDetectionCounter
            SC_DTC9A0725_AVASOutputClip_ResetEventDebounceStatus: operation=DTC9A0725_AVASOutputClip.ResetEventDebounceStatus
            SC_DTC9A0725_AVASOutputClip_ResetEventStatus: operation=DTC9A0725_AVASOutputClip.ResetEventStatus
            SC_DTC9A0725_AVASOutputClip_SetEventStatus: operation=DTC9A0725_AVASOutputClip.SetEventStatus
            SC_NvMService_AC2_SRBS_Defs_NvBlockNeed_LC_Calibration2_GetErrorStatus: operation=NvMService_AC2_SRBS_Defs_NvBlockNeed_LC_Calibration2.GetErrorStatus
            SC_NvMService_AC2_SRBS_Defs_NvBlockNeed_LC_Calibration2_ReadBlock: operation=NvMService_AC2_SRBS_Defs_NvBlockNeed_LC_Calibration2.ReadBlock
            SC_NvMService_AC2_SRBS_Defs_NvBlockNeed_LC_Calibration2_RestoreBlockDefaults: operation=NvMService_AC2_SRBS_Defs_NvBlockNeed_LC_Calibration2.RestoreBlockDefaults
            SC_NvMService_AC2_SRBS_Defs_NvBlockNeed_LC_Calibration2_SetRamBlockStatus: operation=NvMService_AC2_SRBS_Defs_NvBlockNeed_LC_Calibration2.SetRamBlockStatus
            SC_NvMService_AC2_SRBS_Defs_NvBlockNeed_LC_Calibration2_WriteBlock: operation=NvMService_AC2_SRBS_Defs_NvBlockNeed_LC_Calibration2.WriteBlock
        EOL_Get_SpeakerStatus_0xFDD2_EOL_Get_SpeakerStatus_0xFDD2
        NvBlockNeed_LC_Calibration_JobFinished
        AMP_EOL_Read_Operation
        NvBlockNeed_LC_Calibration2_JobFinished
      swc service dependency NvBlockNeed_LC_Calibration
        assigned-datas:
          role=ramBlock, used-data-element=NvBlockNeed_LC_Calibration_MirrorBlock
          role=defaultValue, used-parameter-element=NvBlockNeed_LC_Calibration_DefaultValue
        assigned-ports:
          port-prototype=NvMService_AC2_SRBS_Defs_NvBlockNeed_LC_Calibration, role=NvMService_AC2_SRBS_Defs
          port-prototype=NvMNotifyJobFinished_NvBlockNeed_LC_Calibration, role=NvMNotifyJobFinished
        service-needs:
          nv block needs NvBlockNeed_LC_Calibration: n-data-sets=0, ram-block-status-control=API, reliability=NO-PROTECTION, restore-at-start=false, store-at-shutdown=false
      swc service dependency NvBlockNeed_LC_Calibration2
        assigned-datas:
          role=ramBlock, used-data-element=NvBlockNeed_LC_Calibration2_MirrorBlock
          role=defaultValue, used-parameter-element=NvBlockNeed_LC_Calibration2_DefaultValue
        assigned-ports:
          port-prototype=NvMNotifyJobFinished_NvBlockNeed_LC_Calibration2, role=NvMNotifyJobFinished
          port-prototype=NvMService_AC2_SRBS_Defs_NvBlockNeed_LC_Calibration2, role=NvMService_AC2_SRBS_Defs
        service-needs:
          nv block needs NvBlockNeed_LC_Calibration2: n-data-sets=0, ram-block-status-control=API, reliability=NO-PROTECTION, restore-at-start=false, store-at-shutdown=false
      shared-parameters:
        parameter data prototype NvBlockNeed_LC_Calibration_DefaultValue: sw-calibration-access=READ-WRITE, type=A_u8_20, init-value=[64, 64, 64, 64, 0, 0, 0, 0, 0, 0, 64, 64, 64, 64, 0, 0, 0, 0, 0, 0]
        parameter data prototype NvBlockNeed_LC_Calibration2_DefaultValue: sw-calibration-access=READ-WRITE, type=A_u8_20, init-value=[64, 64, 64, 64, 0, 0, 0, 0, 0, 0, 0, 0, 0, 0, 0, 0, 0, 0, 0, 0]
